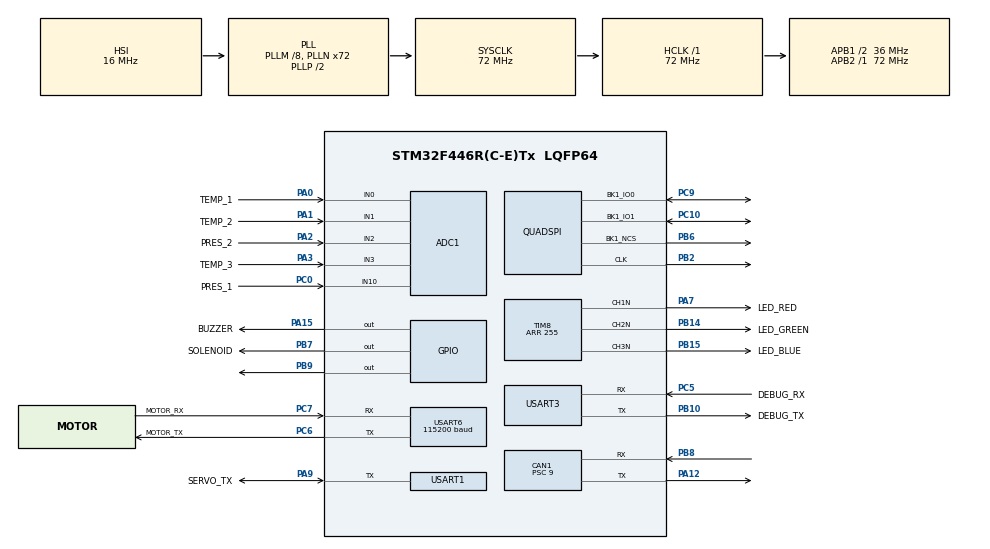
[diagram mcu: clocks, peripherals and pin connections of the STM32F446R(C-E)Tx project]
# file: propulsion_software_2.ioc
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VP_TIM5_VS_ClockSourceINT.Mode=Internal
Dma.USART3_RX.1.Mode=DMA_CIRCULAR
QUADSPI.ClockPrescaler=100
PB10.Mode=Asynchronous
Dma.USART1_RX.5.Mode=DMA_CIRCULAR
Dma.USART3_TX.3.MemInc=DMA_MINC_ENABLE
ADC1.SamplingTime-6\#ChannelRegularConversion=ADC_SAMPLETIME_15CYCLES
PB14.GPIO_Label=LED_GREEN
PC6.GPIO_Label=MOTOR_TX
Dma.USART1_TX.6.PeriphInc=DMA_PINC_DISABLE
PC5.Mode=Asynchronous
Dma.USART3_TX.3.MemDataAlignment=DMA_MDATAALIGN_BYTE
ADC1.Channel-8\#ChannelRegularConversion=ADC_CHANNEL_1
RCC.SYSCLKSource=RCC_SYSCLKSOURCE_PLLCLK
PA9.GPIO_ModeDefaultOD=GPIO_MODE_AF_OD
TIM8.OCNPolarity_1=TIM_OCNPOLARITY_LOW
TIM8.OCNPolarity_2=TIM_OCNPOLARITY_LOW
Dma.USART6_RX.0.Instance=DMA2_Stream1
Dma.USART6_RX.0.FIFOMode=DMA_FIFOMODE_DISABLE
ADC1.Channel-5\#ChannelRegularConversion=ADC_CHANNEL_2
TIM8.OCNPolarity_3=TIM_OCNPOLARITY_LOW
Dma.USART3_RX.1.Instance=DMA1_Stream1
RCC.APB2TimFreq_Value=72000000
PB6.Signal=QUADSPI_BK1_NCS
PC7.Signal=USART6_RX
PB6.Mode=Single Bank 1 2IOs
Dma.USART1_TX.6.Mode=DMA_NORMAL
QUADSPI.FlashSize=26
PB2.Signal=QUADSPI_CLK
Dma.ADC1.2.MemDataAlignment=DMA_MDATAALIGN_HALFWORD
Dma.USART3_RX.1.Priority=DMA_PRIORITY_HIGH
PB14.Mode=PWM Generation2 CH2N
PC9.Mode=Single Bank 1 2IOs
Dma.ADC1.2.Direction=DMA_PERIPH_TO_MEMORY
VP_FREERTOS_VS_CMSIS_V1.Mode=CMSIS_V1
Dma.USART1_TX.6.Direction=DMA_MEMORY_TO_PERIPH
CAN1.Prescaler=9
PB9.Signal=GPIO_Output
Mcu.Package=LQFP64
TIM2.Prescaler=49
Dma.USART3_RX.1.FIFOMode=DMA_FIFOMODE_DISABLE
Dma.USART6_TX.4.Instance=DMA2_Stream6
NVIC.TimeBase=TIM1_UP_TIM10_IRQn
Dma.USART1_RX.5.MemDataAlignment=DMA_MDATAALIGN_BYTE
Dma.USART3_RX.1.Direction=DMA_PERIPH_TO_MEMORY
NVIC.TimeBaseIP=TIM1
PC6.GPIO_PuPd=GPIO_NOPULL
NVIC.DMA2_Stream2_IRQn=true\:5\:0\:true\:false\:true\:true\:false\:true
RCC.APB1TimFreq_Value=72000000
FREERTOS.configGENERATE_RUN_TIME_STATS=1
NVIC.USART1_IRQn=true\:5\:0\:true\:false\:true\:true\:true\:true
CAN1.CalculateTimeBit=4000.00
ADC1.EOCSelection=ADC_EOC_SEQ_CONV
Dma.USART6_TX.4.Mode=DMA_NORMAL
Dma.ADC1.2.Mode=DMA_CIRCULAR
CAN1.CalculateTimeQuantum=250.0
NVIC.QUADSPI_IRQn=true\:5\:0\:true\:false\:true\:true\:true\:true
FREERTOS.Tasks01=defaultTask,-3,128,StartDefaultTask,Default,NULL,Static,defaultTaskBuffer,defaultTaskControlBlock
Dma.USART6_RX.0.PeriphInc=DMA_PINC_DISABLE
PA9.GPIO_Label=SERVO_TX
FREERTOS.INCLUDE_vTaskDelayUntil=1
CAN1.CalculateBaudRate=250000
Dma.USART6_TX.4.FIFOMode=DMA_FIFOMODE_DISABLE
PC6.Signal=USART6_TX
Dma.USART3_RX.1.MemDataAlignment=DMA_MDATAALIGN_BYTE
NVIC.DMA2_Stream1_IRQn=true\:5\:0\:true\:false\:true\:true\:false\:true
ADC1.ExternalTrigConvEdge=ADC_EXTERNALTRIGCONVEDGE_RISINGFALLING
PC0.Signal=ADCx_IN10
RCC.APB1CLKDivider=RCC_HCLK_DIV2
Dma.USART3_TX.3.PeriphInc=DMA_PINC_DISABLE
PA0-WKUP.GPIO_Label=TEMP_1
PA0-WKUP.Signal=ADCx_IN0
ADC1.Channel-7\#ChannelRegularConversion=ADC_CHANNEL_0
Dma.ADC1.2.MemInc=DMA_MINC_ENABLE
PC6.Mode=Asynchronous
TIM8.Channel-PWM\ Generation3\ CH3N=TIM_CHANNEL_3
PA9.Signal=USART1_TX
VP_TIM8_VS_ClockSourceINT.Mode=Internal
Dma.USART6_TX.4.PeriphDataAlignment=DMA_PDATAALIGN_BYTE
NVIC.DMA2_Stream6_IRQn=true\:5\:0\:true\:false\:true\:true\:false\:true
PB10.Signal=USART3_TX
PB14.Signal=TIM8_CH2N
FREERTOS.MEMORY_ALLOCATION=1
TIM8.AutoReloadPreload=TIM_AUTORELOAD_PRELOAD_DISABLE
Dma.USART1_RX.5.PeriphDataAlignment=DMA_PDATAALIGN_BYTE
PB15.GPIO_Label=LED_BLUE
PA1.GPIO_Label=TEMP_2
ADC1.DMAContinuousRequests=ENABLE
TIM2.Period=1000
ADC1.Rank-9\#ChannelRegularConversion=5
Dma.ADC1.2.Instance=DMA2_Stream0
Dma.USART3_TX.3.Mode=DMA_NORMAL
ADC1.ExternalTrigConv=ADC_EXTERNALTRIGCONV_T3_TRGO
TIM8.Period=255
PC7.GPIO_Label=MOTOR_RX
ADC1.master=1
USART1.VirtualMode=VM_ASYNC
ProjectManager.HeapSize=0x200
Dma.ADC1.2.FIFOMode=DMA_FIFOMODE_DISABLE
ADC1.SamplingTime-5\#ChannelRegularConversion=ADC_SAMPLETIME_15CYCLES
NVIC.TIM1_UP_TIM10_IRQn=true\:0\:0\:true\:false\:true\:false\:false\:true
NVIC.PriorityGroup=NVIC_PRIORITYGROUP_4
Dma.USART6_RX.0.MemInc=DMA_MINC_ENABLE
PB8.Mode=CAN_Activate
TIM2.AutoReloadPreload=TIM_AUTORELOAD_PRELOAD_DISABLE
ADC1.SamplingTime-9\#ChannelRegularConversion=ADC_SAMPLETIME_15CYCLES
Dma.USART1_TX.6.Priority=DMA_PRIORITY_LOW
ADC1.Rank-5\#ChannelRegularConversion=1
NVIC.CAN1_RX0_IRQn=true\:5\:0\:true\:false\:true\:true\:true\:true
TIM8.CounterMode=TIM_COUNTERMODE_UP
Dma.USART3_TX.3.Priority=DMA_PRIORITY_LOW
Mcu.Family=STM32F4
Dma.USART1_RX.5.FIFOMode=DMA_FIFOMODE_DISABLE
NVIC.USART3_IRQn=true\:5\:0\:true\:false\:true\:true\:true\:true
Dma.USART1_RX.5.Priority=DMA_PRIORITY_VERY_HIGH
RCC.CortexFreq_Value=72000000
Dma.USART3_TX.3.PeriphDataAlignment=DMA_PDATAALIGN_BYTE
ADC1.ContinuousConvMode=DISABLE
Dma.USART1_RX.5.Direction=DMA_PERIPH_TO_MEMORY
USART1.BaudRate=115200
SH.ADCx_IN2.0=ADC1_IN2,IN2
PC10.Signal=QUADSPI_BK1_IO1
Dma.USART6_TX.4.PeriphInc=DMA_PINC_DISABLE
Dma.USART1_TX.6.PeriphDataAlignment=DMA_PDATAALIGN_BYTE
PC0.GPIO_Label=PRES_1
PB15.Signal=TIM8_CH3N
ProjectManager.StackSize=0x400
PA15.GPIO_Label=BUZZER
Dma.USART1_RX.5.MemInc=DMA_MINC_ENABLE
PA12.Signal=CAN1_TX
Dma.USART3_RX.1.MemInc=DMA_MINC_ENABLE
Dma.USART6_RX.0.Direction=DMA_PERIPH_TO_MEMORY
PC6.GPIO_ModeDefaultPP=GPIO_MODE_AF_PP
RCC.HCLKFreq_Value=72000000
SH.ADCx_IN3.0=ADC1_IN3,IN3
TIM3.Period=1125
Dma.USART3_RX.1.PeriphDataAlignment=DMA_PDATAALIGN_BYTE
NVIC.DMA2_Stream0_IRQn=true\:5\:0\:true\:false\:true\:true\:false\:true
RCC.AHBFreq_Value=72000000
ADC1.Channel-6\#ChannelRegularConversion=ADC_CHANNEL_10
Dma.USART3_TX.3.Direction=DMA_MEMORY_TO_PERIPH
USART6.OverSampling=UART_OVERSAMPLING_16
VP_SYS_VS_tim1.Mode=TIM1
TIM3.Prescaler=0
TIM8.Pulse-PWM\ Generation2\ CH2N=128
PB7.Signal=GPIO_Output
SH.ADCx_IN0.0=ADC1_IN0,IN0
PB7.GPIO_Label=SOLENOID
NVIC.DMA2_Stream7_IRQn=true\:5\:0\:true\:false\:true\:true\:false\:true
Dma.USART6_TX.4.Direction=DMA_MEMORY_TO_PERIPH
USART6.VirtualMode=VM_ASYNC
PA2.GPIO_Label=PRES_2
TIM8.Channel-PWM\ Generation2\ CH2N=TIM_CHANNEL_2
Dma.USART6_RX.0.Mode=DMA_CIRCULAR
PA15.Signal=GPIO_Output
USART6.BaudRate=115200
Dma.USART6_RX.0.MemDataAlignment=DMA_MDATAALIGN_BYTE
TIM2.TIM_MasterOutputTrigger=TIM_TRGO_RESET
SH.ADCx_IN1.0=ADC1_IN1,IN1
Dma.Request2=ADC1
Dma.Request1=USART3_RX
Dma.Request4=USART6_TX
Dma.Request3=USART3_TX
Dma.Request6=USART1_TX
Dma.Request5=USART1_RX
PC5.Signal=USART3_RX
ADC1.Rank-6\#ChannelRegularConversion=2
Dma.Request0=USART6_RX
ADC1.SamplingTime-8\#ChannelRegularConversion=ADC_SAMPLETIME_15CYCLES
TIM8.Pulse-PWM\ Generation1\ CH1N=128
VP_TIM3_VS_ClockSourceINT.Mode=Internal
PA3.Signal=ADCx_IN3
Dma.USART1_TX.6.MemInc=DMA_MINC_ENABLE
Dma.USART6_TX.4.MemInc=DMA_MINC_ENABLE
TIM3.CounterMode=TIM_COUNTERMODE_UP
PA7.Mode=PWM Generation1 CH1N
TIM2.CounterMode=TIM_COUNTERMODE_DOWN
ADC1.Rank-8\#ChannelRegularConversion=4
Dma.ADC1.2.PeriphDataAlignment=DMA_PDATAALIGN_HALFWORD
Dma.USART6_TX.4.Priority=DMA_PRIORITY_LOW
PC10.Mode=Single Bank 1 2IOs
NVIC.DMA1_Stream1_IRQn=true\:5\:0\:true\:false\:true\:true\:false\:true
PA9.GPIO_PuPd=GPIO_PULLUP
NVIC.USART6_IRQn=true\:5\:0\:true\:false\:true\:true\:true\:true
TIM8.Channel-PWM\ Generation1\ CH1N=TIM_CHANNEL_1
PA9.Mode=Half_duplex(single_wire_mode)
Dma.USART1_RX.5.PeriphInc=DMA_PINC_DISABLE
CAN1.BS2=CAN_BS2_2TQ
CAN1.BS1=CAN_BS1_13TQ
ProjectManager.TargetToolchain=STM32CubeIDE
Dma.USART1_TX.6.FIFOMode=DMA_FIFOMODE_DISABLE
PB10.GPIO_Label=DEBUG_TX
Dma.USART3_TX.3.FIFOMode=DMA_FIFOMODE_DISABLE
RCC.USBFreq_Value=48000000
PA1.Signal=ADCx_IN1
Dma.USART1_TX.6.Instance=DMA2_Stream7
Dma.USART3_TX.3.Instance=DMA1_Stream3
board=custom
RCC.VCOOutputFreq_Value=144000000
PB15.Mode=PWM Generation3 CH3N
RCC.APB2Freq_Value=72000000
VP_TIM2_VS_ClockSourceINT.Mode=Internal
ADC1.NbrOfConversion=5
Mcu.Name=STM32F446R(C-E)Tx
PA2.Signal=ADCx_IN2
ADC1.Channel-9\#ChannelRegularConversion=ADC_CHANNEL_3
RCC.SYSCLKFreq_VALUE=72000000
Dma.USART6_RX.0.PeriphDataAlignment=DMA_PDATAALIGN_BYTE
Dma.ADC1.2.Priority=DMA_PRIORITY_HIGH
PA7.GPIO_Label=LED_RED
PA12.Mode=CAN_Activate
Dma.ADC1.2.PeriphInc=DMA_PINC_DISABLE
TIM5.Prescaler=719
PC5.GPIO_Label=DEBUG_RX
USART3.VirtualMode=VM_ASYNC
TIM3.TIM_MasterSlaveMode=TIM_MASTERSLAVEMODE_DISABLE
PB2.Mode=Single Bank 1 2IOs
SH.ADCx_IN10.0=ADC1_IN10,IN10
Dma.USART6_TX.4.MemDataAlignment=DMA_MDATAALIGN_BYTE
Dma.USART6_RX.0.Priority=DMA_PRIORITY_VERY_HIGH
ADC1.Rank-7\#ChannelRegularConversion=3
RCC.PLLQ=3
ADC1.NbrOfConversionFlag=1
RCC.PLLM=8
RCC.PLLN=72
Dma.USART1_RX.5.Instance=DMA2_Stream2
PB8.Signal=CAN1_RX
Dma.USART1_TX.6.MemDataAlignment=DMA_MDATAALIGN_BYTE
NVIC.DMA1_Stream3_IRQn=true\:5\:0\:true\:false\:true\:true\:false\:true
PC9.Signal=QUADSPI_BK1_IO0
ADC1.SamplingTime-7\#ChannelRegularConversion=ADC_SAMPLETIME_15CYCLES
TIM3.TIM_MasterOutputTrigger=TIM_TRGO_UPDATE
PC7.Mode=Asynchronous
RCC.APB1Freq_Value=36000000
Dma.USART3_RX.1.PeriphInc=DMA_PINC_DISABLE
PA3.GPIO_Label=TEMP_3
PA7.Signal=TIM8_CH1N

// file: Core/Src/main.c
/* USER CODE BEGIN Header */
/**
  ******************************************************************************
  * @file           : main.c
  * @brief          : Main program body
  ******************************************************************************
  * @attention
  *
  * <h2><center>&copy; Copyright (c) 2020 STMicroelectronics.
  * All rights reserved.</center></h2>
  *
  * This software component is licensed by ST under BSD 3-Clause license,
  * the "License"; You may not use this file except in compliance with the
  * License. You may obtain a copy of the License at:
  *                        opensource.org/licenses/BSD-3-Clause
  *
  ******************************************************************************
  */
/* USER CODE END Header */
#include "main.h"
#include "cmsis_os.h"
#include "adc.h"
#include "can.h"
#include "dma.h"
#include "quadspi.h"
#include "tim.h"
#include "usart.h"
#include "gpio.h"

/* USER CODE BEGIN Includes */
#include <threads.h>
#include <led.h>
#include <cmsis_os.h>

/* USER CODE END Includes */

void SystemClock_Config(void);
void MX_FREERTOS_Init(void);

int main(void)
{

  /* MCU Configuration--------------------------------------------------------*/

  /* Reset of all peripherals, Initializes the Flash interface and the Systick. */
  HAL_Init();

  /* Configure the system clock */
  SystemClock_Config();

  /* Initialize all configured peripherals */
  MX_GPIO_Init();
  MX_DMA_Init();
  MX_ADC1_Init();
  MX_TIM8_Init();
  MX_TIM2_Init();
  MX_USART6_UART_Init();
  MX_USART3_UART_Init();
  MX_QUADSPI_Init();
  MX_TIM3_Init();
  MX_CAN1_Init();
  MX_USART1_UART_Init();
  MX_TIM5_Init();
  /* USER CODE BEGIN 2 */

  threads_init();

  /* USER CODE END 2 */

  /* Call init function for freertos objects (in freertos.c) */
  MX_FREERTOS_Init();
  /* Start scheduler */
  osKernelStart();

  /* We should never get here as control is now taken by the scheduler */
  /* Infinite loop */
  /* USER CODE BEGIN WHILE */

  while (1)
  {
	osDelay(1000);
    /* USER CODE END WHILE */

  }
}

void SystemClock_Config(void)
{
  RCC_OscInitTypeDef RCC_OscInitStruct = {0};
  RCC_ClkInitTypeDef RCC_ClkInitStruct = {0};

  /** Configure the main internal regulator output voltage
  */
  __HAL_RCC_PWR_CLK_ENABLE();
  __HAL_PWR_VOLTAGESCALING_CONFIG(PWR_REGULATOR_VOLTAGE_SCALE3);
  /** Initializes the RCC Oscillators according to the specified parameters
  * in the RCC_OscInitTypeDef structure.
  */
  RCC_OscInitStruct.OscillatorType = RCC_OSCILLATORTYPE_HSI;
  RCC_OscInitStruct.HSIState = RCC_HSI_ON;
  RCC_OscInitStruct.HSICalibrationValue = RCC_HSICALIBRATION_DEFAULT;
  RCC_OscInitStruct.PLL.PLLState = RCC_PLL_ON;
  RCC_OscInitStruct.PLL.PLLSource = RCC_PLLSOURCE_HSI;
  RCC_OscInitStruct.PLL.PLLM = 8;
  RCC_OscInitStruct.PLL.PLLN = 72;
  RCC_OscInitStruct.PLL.PLLP = RCC_PLLP_DIV2;
  RCC_OscInitStruct.PLL.PLLQ = 3;
  RCC_OscInitStruct.PLL.PLLR = 2;
  if (HAL_RCC_OscConfig(&RCC_OscInitStruct) != HAL_OK)
  {
    Error_Handler();
  }
  /** Initializes the CPU, AHB and APB buses clocks
  */
  RCC_ClkInitStruct.ClockType = RCC_CLOCKTYPE_HCLK|RCC_CLOCKTYPE_SYSCLK
                              |RCC_CLOCKTYPE_PCLK1|RCC_CLOCKTYPE_PCLK2;
  RCC_ClkInitStruct.SYSCLKSource = RCC_SYSCLKSOURCE_PLLCLK;
  RCC_ClkInitStruct.AHBCLKDivider = RCC_SYSCLK_DIV1;
  RCC_ClkInitStruct.APB1CLKDivider = RCC_HCLK_DIV2;
  RCC_ClkInitStruct.APB2CLKDivider = RCC_HCLK_DIV1;

  if (HAL_RCC_ClockConfig(&RCC_ClkInitStruct, FLASH_LATENCY_2) != HAL_OK)
  {
    Error_Handler();
  }
}

 /**
  * @brief  Period elapsed callback in non blocking mode
  * @note   This function is called  when TIM1 interrupt took place, inside
  * HAL_TIM_IRQHandler(). It makes a direct call to HAL_IncTick() to increment
  * a global variable "uwTick" used as application time base.
  * @param  htim : TIM handle
  * @retval None
  */
void HAL_TIM_PeriodElapsedCallback(TIM_HandleTypeDef *htim)
{
  if (htim->Instance == TIM1) {
    HAL_IncTick();
  }
}

void Error_Handler(void)
{
}

/************************ (C) COPYRIGHT STMicroelectronics *****END OF FILE****/

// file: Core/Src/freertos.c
/* USER CODE BEGIN Header */
/**
  ******************************************************************************
  * File Name          : freertos.c
  * Description        : Code for freertos applications
  ******************************************************************************
  * @attention
  *
  * <h2><center>&copy; Copyright (c) 2021 STMicroelectronics.
  * All rights reserved.</center></h2>
  *
  * This software component is licensed by ST under Ultimate Liberty license
  * SLA0044, the "License"; You may not use this file except in compliance with
  * the License. You may obtain a copy of the License at:
  *                             www.st.com/SLA0044
  *
  ******************************************************************************
  */
/* USER CODE END Header */

#include "FreeRTOS.h"
#include "task.h"
#include "main.h"
#include "cmsis_os.h"

osThreadId defaultTaskHandle;
uint32_t defaultTaskBuffer[ 128 ];
osStaticThreadDef_t defaultTaskControlBlock;

void StartDefaultTask(void const * argument);

void MX_FREERTOS_Init(void); /* (MISRA C 2004 rule 8.1) */

/* GetIdleTaskMemory prototype (linked to static allocation support) */
void vApplicationGetIdleTaskMemory( StaticTask_t **ppxIdleTaskTCBBuffer, StackType_t **ppxIdleTaskStackBuffer, uint32_t *pulIdleTaskStackSize );

/* USER CODE BEGIN GET_IDLE_TASK_MEMORY */
static StaticTask_t xIdleTaskTCBBuffer;
static StackType_t xIdleStack[configMINIMAL_STACK_SIZE];

void vApplicationGetIdleTaskMemory( StaticTask_t **ppxIdleTaskTCBBuffer, StackType_t **ppxIdleTaskStackBuffer, uint32_t *pulIdleTaskStackSize )
{
  *ppxIdleTaskTCBBuffer = &xIdleTaskTCBBuffer;
  *ppxIdleTaskStackBuffer = &xIdleStack[0];
  *pulIdleTaskStackSize = configMINIMAL_STACK_SIZE;
  /* place for user code */
}
/* USER CODE END GET_IDLE_TASK_MEMORY */

void MX_FREERTOS_Init(void) {

  /* Create the thread(s) */
  /* definition and creation of defaultTask */
  osThreadStaticDef(defaultTask, StartDefaultTask, osPriorityNormal, 0, 128, defaultTaskBuffer, &defaultTaskControlBlock);
  defaultTaskHandle = osThreadCreate(osThread(defaultTask), NULL);

}

void StartDefaultTask(void const * argument)
{
  for(;;)
  {
    osDelay(1);
  }
}

/************************ (C) COPYRIGHT STMicroelectronics *****END OF FILE****/
